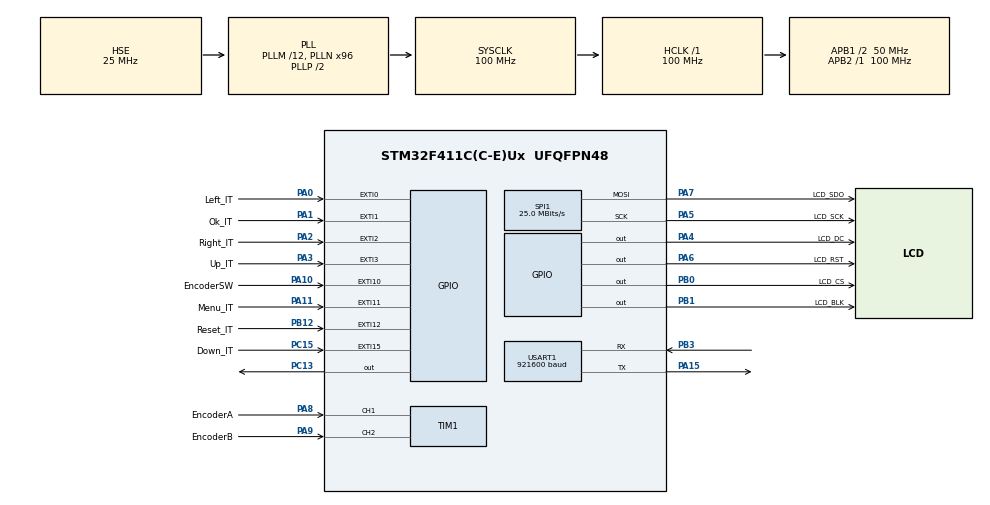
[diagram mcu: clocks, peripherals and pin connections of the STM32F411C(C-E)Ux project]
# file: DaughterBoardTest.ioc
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Dma.MEMTOMEM.1.Direction=DMA_MEMORY_TO_MEMORY
Dma.MEMTOMEM.1.FIFOMode=DMA_FIFOMODE_ENABLE
Dma.MEMTOMEM.1.FIFOThreshold=DMA_FIFO_THRESHOLD_FULL
Dma.MEMTOMEM.1.Instance=DMA2_Stream0
Dma.MEMTOMEM.1.MemBurst=DMA_MBURST_SINGLE
Dma.MEMTOMEM.1.MemDataAlignment=DMA_MDATAALIGN_HALFWORD
Dma.MEMTOMEM.1.MemInc=DMA_MINC_ENABLE
Dma.MEMTOMEM.1.Mode=DMA_NORMAL
Dma.MEMTOMEM.1.PeriphBurst=DMA_PBURST_SINGLE
Dma.MEMTOMEM.1.PeriphDataAlignment=DMA_PDATAALIGN_HALFWORD
Dma.MEMTOMEM.1.PeriphInc=DMA_PINC_ENABLE
Dma.MEMTOMEM.1.Priority=DMA_PRIORITY_LOW
Dma.Request0=SPI1_TX
Dma.Request1=MEMTOMEM
Dma.SPI1_TX.0.Direction=DMA_MEMORY_TO_PERIPH
Dma.SPI1_TX.0.FIFOMode=DMA_FIFOMODE_DISABLE
Dma.SPI1_TX.0.Instance=DMA2_Stream2
Dma.SPI1_TX.0.MemDataAlignment=DMA_MDATAALIGN_BYTE
Dma.SPI1_TX.0.MemInc=DMA_MINC_ENABLE
Dma.SPI1_TX.0.Mode=DMA_NORMAL
Dma.SPI1_TX.0.PeriphDataAlignment=DMA_PDATAALIGN_BYTE
Dma.SPI1_TX.0.PeriphInc=DMA_PINC_DISABLE
Dma.SPI1_TX.0.Priority=DMA_PRIORITY_MEDIUM
Mcu.Family=STM32F4
Mcu.Name=STM32F411C(C-E)Ux
Mcu.Package=UFQFPN48
NVIC.DMA2_Stream0_IRQn=true\:0\:0\:false\:false\:true\:true\:true\:true
NVIC.DMA2_Stream2_IRQn=true\:0\:0\:false\:false\:true\:false\:true\:true
NVIC.EXTI0_IRQn=true\:0\:0\:false\:false\:true\:true\:true\:true
NVIC.EXTI15_10_IRQn=true\:0\:0\:false\:false\:true\:true\:true\:true
NVIC.EXTI1_IRQn=true\:0\:0\:false\:false\:true\:true\:true\:true
NVIC.EXTI2_IRQn=true\:0\:0\:false\:false\:true\:true\:true\:true
NVIC.EXTI3_IRQn=true\:0\:0\:false\:false\:true\:true\:true\:true
NVIC.PriorityGroup=NVIC_PRIORITYGROUP_4
NVIC.TIM2_IRQn=true\:0\:0\:false\:false\:true\:true\:true\:true
PA0-WKUP.GPIO_Label=Left_IT
PA0-WKUP.GPIO_ModeDefaultEXTI=GPIO_MODE_IT_FALLING
PA0-WKUP.GPIO_PuPd=GPIO_PULLUP
PA0-WKUP.Signal=GPXTI0
PA1.GPIO_Label=Ok_IT
PA1.GPIO_ModeDefaultEXTI=GPIO_MODE_IT_FALLING
PA1.GPIO_PuPd=GPIO_PULLUP
PA1.Signal=GPXTI1
PA10.GPIO_Label=EncoderSW
PA10.GPIO_ModeDefaultEXTI=GPIO_MODE_IT_FALLING
PA10.GPIO_PuPd=GPIO_PULLUP
PA10.Signal=GPXTI10
PA11.GPIO_Label=Menu_IT
PA11.GPIO_ModeDefaultEXTI=GPIO_MODE_IT_FALLING
PA11.GPIO_PuPd=GPIO_PULLUP
PA11.Signal=GPXTI11
PA13.Mode=Serial_Wire
PA13.Signal=SYS_JTMS-SWDIO
PA14.Mode=Serial_Wire
PA14.Signal=SYS_JTCK-SWCLK
PA15.Mode=Asynchronous
PA15.Signal=USART1_TX
PA2.GPIO_Label=Right_IT
PA2.GPIO_ModeDefaultEXTI=GPIO_MODE_IT_FALLING
PA2.GPIO_PuPd=GPIO_PULLUP
PA2.Signal=GPXTI2
PA3.GPIO_Label=Up_IT
PA3.GPIO_ModeDefaultEXTI=GPIO_MODE_IT_FALLING
PA3.GPIO_PuPd=GPIO_PULLUP
PA3.Signal=GPXTI3
PA4.GPIO_Label=LCD_DC
PA4.GPIO_PuPd=GPIO_PULLUP
PA4.GPIO_Speed=GPIO_SPEED_FREQ_VERY_HIGH
PA4.PinState=GPIO_PIN_SET
PA4.Signal=GPIO_Output
PA5.GPIO_Label=LCD_SCK
PA5.Mode=TX_Only_Simplex_Unidirect_Master
PA5.Signal=SPI1_SCK
PA6.GPIO_Label=LCD_RST
PA6.GPIO_PuPd=GPIO_PULLUP
PA6.GPIO_Speed=GPIO_SPEED_FREQ_VERY_HIGH
PA6.PinState=GPIO_PIN_SET
PA6.Signal=GPIO_Output
PA7.GPIO_Label=LCD_SDO
PA7.Mode=TX_Only_Simplex_Unidirect_Master
PA7.Signal=SPI1_MOSI
PA8.GPIO_Label=EncoderA
PA8.GPIO_PuPd=GPIO_PULLUP
PA8.Signal=S_TIM1_CH1
PA9.GPIO_Label=EncoderB
PA9.GPIO_PuPd=GPIO_PULLUP
PA9.Signal=S_TIM1_CH2
PB0.GPIO_Label=LCD_CS
PB0.GPIO_ModeDefaultOutputPP=GPIO_MODE_OUTPUT_PP
PB0.GPIO_PuPd=GPIO_PULLUP
PB0.GPIO_Speed=GPIO_SPEED_FREQ_VERY_HIGH
PB0.PinState=GPIO_PIN_SET
PB0.Signal=GPIO_Output
PB1.GPIO_Label=LCD_BLK
PB1.GPIO_PuPd=GPIO_PULLUP
PB1.GPIO_Speed=GPIO_SPEED_FREQ_VERY_HIGH
PB1.PinState=GPIO_PIN_SET
PB1.Signal=GPIO_Output
PB12.GPIO_Label=Reset_IT
PB12.GPIO_ModeDefaultEXTI=GPIO_MODE_IT_FALLING
PB12.GPIO_PuPd=GPIO_PULLUP
PB12.Signal=GPXTI12
PB3.Mode=Asynchronous
PB3.Signal=USART1_RX
PC13-ANTI_TAMP.Signal=GPIO_Output
PC15-OSC32_OUT.GPIO_Label=Down_IT
PC15-OSC32_OUT.GPIO_ModeDefaultEXTI=GPIO_MODE_IT_FALLING
PC15-OSC32_OUT.GPIO_PuPd=GPIO_PULLUP
PC15-OSC32_OUT.Signal=GPXTI15
PH0\ -\ OSC_IN.Mode=HSE-External-Oscillator
PH0\ -\ OSC_IN.Signal=RCC_OSC_IN
PH1\ -\ OSC_OUT.Mode=HSE-External-Oscillator
PH1\ -\ OSC_OUT.Signal=RCC_OSC_OUT
ProjectManager.HeapSize=0x200
ProjectManager.StackSize=0x400
ProjectManager.TargetToolchain=STM32CubeIDE
RCC.48MHZClocksFreq_Value=50000000
RCC.AHBFreq_Value=100000000
RCC.APB1CLKDivider=RCC_HCLK_DIV2
RCC.APB1Freq_Value=50000000
RCC.APB1TimFreq_Value=100000000
RCC.APB2Freq_Value=100000000
RCC.APB2TimFreq_Value=100000000
RCC.CortexFreq_Value=100000000
RCC.HCLKFreq_Value=100000000
RCC.HSE_VALUE=25000000
RCC.HSI_VALUE=16000000
RCC.LSE_VALUE=32768
RCC.PLLM=12
RCC.PLLN=96
RCC.PLLSourceVirtual=RCC_PLLSOURCE_HSE
RCC.SYSCLKFreq_VALUE=100000000
RCC.SYSCLKSource=RCC_SYSCLKSOURCE_PLLCLK
RCC.VCOOutputFreq_Value=200000000
SH.S_TIM1_CH1.0=TIM1_CH1,Encoder_Interface
SH.S_TIM1_CH2.0=TIM1_CH2,Encoder_Interface
SPI1.BaudRatePrescaler=SPI_BAUDRATEPRESCALER_4
SPI1.CLKPolarity=SPI_POLARITY_HIGH
SPI1.CalculateBaudRate=25.0 MBits/s
SPI1.Direction=SPI_DIRECTION_2LINES
SPI1.Mode=SPI_MODE_MASTER
SPI1.VirtualType=VM_MASTER
TIM1.IC1Filter=10
TIM1.IC2Filter=10
TIM2.AutoReloadPreload=TIM_AUTORELOAD_PRELOAD_ENABLE
TIM2.Period=49999
TIM2.Prescaler=1
USART1.BaudRate=921600
USART1.Parity=PARITY_EVEN
USART1.VirtualMode=VM_ASYNC
USART1.WordLength=WORDLENGTH_9B
VP_TIM2_VS_ClockSourceINT.Mode=Internal
board=custom

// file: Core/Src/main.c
#include "main.h"
#include "lcd.h"
#include "UI.h"
#include <stdio.h>
#include <string.h>

#define LCD_TEST
#define LCD_UI_DESIGN

#define TimerMiddleValue 0x7FFF //0xFFFF/2
#define TimerValue TimerMiddleValue>>2 //1FFF
#define EncoderGetVal(x) x = (int32_t)(((TIM1 -> CNT)>>2) - (TimerValue))

SPI_HandleTypeDef hspi1;
DMA_HandleTypeDef hdma_spi1_tx;

TIM_HandleTypeDef htim1;
TIM_HandleTypeDef htim2;

UART_HandleTypeDef huart1;

DMA_HandleTypeDef hdma_memtomem_dma2_stream0;

typedef enum bool
{
	false,
	true
}bool;

void SystemClock_Config(void);
static void MX_GPIO_Init(void);
static void MX_DMA_Init(void);
static void MX_USART1_UART_Init(void);
static void MX_SPI1_Init(void);
static void MX_TIM1_Init(void);
static void MX_TIM2_Init(void);
static void vTaskEncoder(void);

char *Buffer = "SI!";

__IO uint32_t transferErrorDetected;    /* Set to 1 if an error transfer is detected */
__IO uint32_t transferCompleteDetected; /* Set to 1 if transfer is correctly completed */

bool ParsedFlag = true;
MenuStage menuStage = sInitialAnim;
Input input;

int main(void)
{
  HAL_Init();
  SystemClock_Config();
  MX_GPIO_Init();
  MX_DMA_Init();
  MX_USART1_UART_Init();
  MX_SPI1_Init();
  MX_TIM1_Init();
  MX_TIM2_Init();

  LCD_init();

#ifdef LCD_TEST
  LCD_Test();
  UG_FillScreen(0);
  UG_Update();
#endif

  HAL_TIM_Encoder_Start(&htim1, TIM_CHANNEL_ALL);
  HAL_TIM_Base_Start_IT(&htim2);
  while (1)
  {
	  vTaskEncoder();
	  vTaskUI(&menuStage, &input);
	  ParsedFlag = true;
	  while(ParsedFlag);
  }
}

static void vTaskEncoder(void)
{
	static uint16_t EncoderCount = TimerMiddleValue;
	static uint16_t EncoderPastCount = TimerMiddleValue;
	char Buffer[32] = "";

	EncoderGetVal(EncoderCount);
	if(EncoderCount != EncoderPastCount)
	{
		sprintf(Buffer, "Encoder: %d!", (int)EncoderCount);
		HAL_UART_Transmit(&huart1, (uint8_t*)Buffer, strlen(Buffer), 100);
	}
	EncoderPastCount = EncoderCount;
}

void HAL_GPIO_EXTI_Callback(uint16_t GPIO_Pin)
{
	if(GPIO_Pin == Ok_IT_Pin)
	{
		char *Buffer = "OK!";
		HAL_UART_Transmit(&huart1, (uint8_t*)Buffer, 3, 100);
		HAL_GPIO_TogglePin(GPIOC, GPIO_PIN_13);
		input = iOk;
	}
	else if(GPIO_Pin == Up_IT_Pin)
	{
		char *Buffer = "Up!";
		HAL_UART_Transmit(&huart1, (uint8_t*)Buffer, 3, 100);
		HAL_GPIO_TogglePin(GPIOC, GPIO_PIN_13);
		input = iUp;
	}
	else if(GPIO_Pin == Down_IT_Pin)
	{
		char *Buffer = "Down!";
		HAL_UART_Transmit(&huart1, (uint8_t*)Buffer, 5, 100);
		HAL_GPIO_TogglePin(GPIOC, GPIO_PIN_13);
		input = iDown;
	}
	else if(GPIO_Pin == Right_IT_Pin)
	{
		char *Buffer = "Right!";
		HAL_UART_Transmit(&huart1, (uint8_t*)Buffer, 6, 100);
		HAL_GPIO_TogglePin(GPIOC, GPIO_PIN_13);
		input = iRight;
	}
	else if(GPIO_Pin == Left_IT_Pin)
	{
		char *Buffer = "Left!";
		HAL_UART_Transmit(&huart1, (uint8_t*)Buffer, 5, 100);
		HAL_GPIO_TogglePin(GPIOC, GPIO_PIN_13);
		input = iLeft;
	}
	else if(GPIO_Pin == Menu_IT_Pin)
	{
		char *Buffer = "Menu!";
		HAL_UART_Transmit(&huart1, (uint8_t*)Buffer, 5, 100);
		HAL_GPIO_TogglePin(GPIOC, GPIO_PIN_13);
		input = iMenu;
	}
	else if(GPIO_Pin == Reset_IT_Pin)
	{
		char *Buffer = "Reset!";
		HAL_UART_Transmit(&huart1, (uint8_t*)Buffer, 6, 100);
		HAL_GPIO_TogglePin(GPIOC, GPIO_PIN_13);
		input = iReset;
	}
	else if(GPIO_Pin == EncoderSW_Pin)
	{
		char *Buffer = "EncoderSW!";
		HAL_UART_Transmit(&huart1, (uint8_t*)Buffer, 10, 100);
		HAL_GPIO_TogglePin(GPIOC, GPIO_PIN_13);
		input = iEncoder;
	}
}

void HAL_TIM_PeriodElapsedCallback(TIM_HandleTypeDef *htim)
{
	ParsedFlag = false;
}

static void TransferComplete(DMA_HandleTypeDef *DmaHandle)
{
  transferCompleteDetected = 1;
}

static void TransferError(DMA_HandleTypeDef *DmaHandle)
{
  transferErrorDetected = 1;
}

void SystemClock_Config(void)
{
  RCC_OscInitTypeDef RCC_OscInitStruct = {0};
  RCC_ClkInitTypeDef RCC_ClkInitStruct = {0};

  /** Configure the main internal regulator output voltage
  */
  __HAL_RCC_PWR_CLK_ENABLE();
  __HAL_PWR_VOLTAGESCALING_CONFIG(PWR_REGULATOR_VOLTAGE_SCALE1);

  /** Initializes the RCC Oscillators according to the specified parameters
  * in the RCC_OscInitTypeDef structure.
  */
  RCC_OscInitStruct.OscillatorType = RCC_OSCILLATORTYPE_HSE;
  RCC_OscInitStruct.HSEState = RCC_HSE_ON;
  RCC_OscInitStruct.PLL.PLLState = RCC_PLL_ON;
  RCC_OscInitStruct.PLL.PLLSource = RCC_PLLSOURCE_HSE;
  RCC_OscInitStruct.PLL.PLLM = 12;
  RCC_OscInitStruct.PLL.PLLN = 96;
  RCC_OscInitStruct.PLL.PLLP = RCC_PLLP_DIV2;
  RCC_OscInitStruct.PLL.PLLQ = 4;
  if (HAL_RCC_OscConfig(&RCC_OscInitStruct) != HAL_OK)
  {
    Error_Handler();
  }

  /** Initializes the CPU, AHB and APB buses clocks
  */
  RCC_ClkInitStruct.ClockType = RCC_CLOCKTYPE_HCLK|RCC_CLOCKTYPE_SYSCLK
                              |RCC_CLOCKTYPE_PCLK1|RCC_CLOCKTYPE_PCLK2;
  RCC_ClkInitStruct.SYSCLKSource = RCC_SYSCLKSOURCE_PLLCLK;
  RCC_ClkInitStruct.AHBCLKDivider = RCC_SYSCLK_DIV1;
  RCC_ClkInitStruct.APB1CLKDivider = RCC_HCLK_DIV2;
  RCC_ClkInitStruct.APB2CLKDivider = RCC_HCLK_DIV1;

  if (HAL_RCC_ClockConfig(&RCC_ClkInitStruct, FLASH_LATENCY_3) != HAL_OK)
  {
    Error_Handler();
  }
}

static void MX_SPI1_Init(void)
{

  /* SPI1 parameter configuration*/
  hspi1.Instance = SPI1;
  hspi1.Init.Mode = SPI_MODE_MASTER;
  hspi1.Init.Direction = SPI_DIRECTION_2LINES;
  hspi1.Init.DataSize = SPI_DATASIZE_8BIT;
  hspi1.Init.CLKPolarity = SPI_POLARITY_HIGH;
  hspi1.Init.CLKPhase = SPI_PHASE_1EDGE;
  hspi1.Init.NSS = SPI_NSS_SOFT;
  hspi1.Init.BaudRatePrescaler = SPI_BAUDRATEPRESCALER_2;
  hspi1.Init.FirstBit = SPI_FIRSTBIT_MSB;
  hspi1.Init.TIMode = SPI_TIMODE_DISABLE;
  hspi1.Init.CRCCalculation = SPI_CRCCALCULATION_DISABLE;
  hspi1.Init.CRCPolynomial = 10;
  if (HAL_SPI_Init(&hspi1) != HAL_OK)
  {
    Error_Handler();
  }

}

static void MX_TIM1_Init(void)
{

  TIM_Encoder_InitTypeDef sConfig = {0};
  TIM_MasterConfigTypeDef sMasterConfig = {0};

  htim1.Instance = TIM1;
  htim1.Init.Prescaler = 0;
  htim1.Init.CounterMode = TIM_COUNTERMODE_UP;
  htim1.Init.Period = 65535;
  htim1.Init.ClockDivision = TIM_CLOCKDIVISION_DIV1;
  htim1.Init.RepetitionCounter = 0;
  htim1.Init.AutoReloadPreload = TIM_AUTORELOAD_PRELOAD_DISABLE;
  sConfig.EncoderMode = TIM_ENCODERMODE_TI1;
  sConfig.IC1Polarity = TIM_ICPOLARITY_RISING;
  sConfig.IC1Selection = TIM_ICSELECTION_DIRECTTI;
  sConfig.IC1Prescaler = TIM_ICPSC_DIV1;
  sConfig.IC1Filter = 10;
  sConfig.IC2Polarity = TIM_ICPOLARITY_RISING;
  sConfig.IC2Selection = TIM_ICSELECTION_DIRECTTI;
  sConfig.IC2Prescaler = TIM_ICPSC_DIV1;
  sConfig.IC2Filter = 10;
  if (HAL_TIM_Encoder_Init(&htim1, &sConfig) != HAL_OK)
  {
    Error_Handler();
  }
  sMasterConfig.MasterOutputTrigger = TIM_TRGO_RESET;
  sMasterConfig.MasterSlaveMode = TIM_MASTERSLAVEMODE_DISABLE;
  if (HAL_TIMEx_MasterConfigSynchronization(&htim1, &sMasterConfig) != HAL_OK)
  {
    Error_Handler();
  }

}

static void MX_TIM2_Init(void)
{

  TIM_ClockConfigTypeDef sClockSourceConfig = {0};
  TIM_MasterConfigTypeDef sMasterConfig = {0};

  htim2.Instance = TIM2;
  htim2.Init.Prescaler = 1;
  htim2.Init.CounterMode = TIM_COUNTERMODE_UP;
  htim2.Init.Period = 49999;
  htim2.Init.ClockDivision = TIM_CLOCKDIVISION_DIV1;
  htim2.Init.AutoReloadPreload = TIM_AUTORELOAD_PRELOAD_ENABLE;
  if (HAL_TIM_Base_Init(&htim2) != HAL_OK)
  {
    Error_Handler();
  }
  sClockSourceConfig.ClockSource = TIM_CLOCKSOURCE_INTERNAL;
  if (HAL_TIM_ConfigClockSource(&htim2, &sClockSourceConfig) != HAL_OK)
  {
    Error_Handler();
  }
  sMasterConfig.MasterOutputTrigger = TIM_TRGO_RESET;
  sMasterConfig.MasterSlaveMode = TIM_MASTERSLAVEMODE_DISABLE;
  if (HAL_TIMEx_MasterConfigSynchronization(&htim2, &sMasterConfig) != HAL_OK)
  {
    Error_Handler();
  }

}

static void MX_USART1_UART_Init(void)
{

  huart1.Instance = USART1;
  huart1.Init.BaudRate = 921600;
  huart1.Init.WordLength = UART_WORDLENGTH_9B;
  huart1.Init.StopBits = UART_STOPBITS_1;
  huart1.Init.Parity = UART_PARITY_EVEN;
  huart1.Init.Mode = UART_MODE_TX_RX;
  huart1.Init.HwFlowCtl = UART_HWCONTROL_NONE;
  huart1.Init.OverSampling = UART_OVERSAMPLING_16;
  if (HAL_UART_Init(&huart1) != HAL_OK)
  {
    Error_Handler();
  }

}

static void MX_DMA_Init(void)
{

  /* DMA controller clock enable */
  __HAL_RCC_DMA2_CLK_ENABLE();

  /* Configure DMA request hdma_memtomem_dma2_stream0 on DMA2_Stream0 */
  hdma_memtomem_dma2_stream0.Instance = DMA2_Stream0;
  hdma_memtomem_dma2_stream0.Init.Channel = DMA_CHANNEL_0;
  hdma_memtomem_dma2_stream0.Init.Direction = DMA_MEMORY_TO_MEMORY;
  hdma_memtomem_dma2_stream0.Init.PeriphInc = DMA_PINC_ENABLE;
  hdma_memtomem_dma2_stream0.Init.MemInc = DMA_MINC_ENABLE;
  hdma_memtomem_dma2_stream0.Init.PeriphDataAlignment = DMA_PDATAALIGN_HALFWORD;
  hdma_memtomem_dma2_stream0.Init.MemDataAlignment = DMA_MDATAALIGN_HALFWORD;
  hdma_memtomem_dma2_stream0.Init.Mode = DMA_NORMAL;
  hdma_memtomem_dma2_stream0.Init.Priority = DMA_PRIORITY_LOW;
  hdma_memtomem_dma2_stream0.Init.FIFOMode = DMA_FIFOMODE_ENABLE;
  hdma_memtomem_dma2_stream0.Init.FIFOThreshold = DMA_FIFO_THRESHOLD_FULL;
  hdma_memtomem_dma2_stream0.Init.MemBurst = DMA_MBURST_SINGLE;
  hdma_memtomem_dma2_stream0.Init.PeriphBurst = DMA_PBURST_SINGLE;
  if (HAL_DMA_Init(&hdma_memtomem_dma2_stream0) != HAL_OK)
  {
    Error_Handler( );
  }

  /* USER CODE BEGIN DMA_Init */
  HAL_DMA_RegisterCallback(&hdma_memtomem_dma2_stream0, HAL_DMA_XFER_CPLT_CB_ID, TransferComplete);
  HAL_DMA_RegisterCallback(&hdma_memtomem_dma2_stream0, HAL_DMA_XFER_ERROR_CB_ID, TransferError);
  /* USER CODE END DMA_Init */

  /* DMA interrupt init */
  /* DMA2_Stream0_IRQn interrupt configuration */
  HAL_NVIC_SetPriority(DMA2_Stream0_IRQn, 0, 0);
  HAL_NVIC_EnableIRQ(DMA2_Stream0_IRQn);
  /* DMA2_Stream2_IRQn interrupt configuration */
  HAL_NVIC_SetPriority(DMA2_Stream2_IRQn, 0, 0);
  HAL_NVIC_EnableIRQ(DMA2_Stream2_IRQn);

}

static void MX_GPIO_Init(void)
{
  GPIO_InitTypeDef GPIO_InitStruct = {0};

  /* GPIO Ports Clock Enable */
  __HAL_RCC_GPIOC_CLK_ENABLE();
  __HAL_RCC_GPIOH_CLK_ENABLE();
  __HAL_RCC_GPIOA_CLK_ENABLE();
  __HAL_RCC_GPIOB_CLK_ENABLE();

  /*Configure GPIO pin Output Level */
  HAL_GPIO_WritePin(GPIOC, GPIO_PIN_13, GPIO_PIN_RESET);

  /*Configure GPIO pin Output Level */
  HAL_GPIO_WritePin(GPIOA, LCD_DC_Pin|LCD_RST_Pin, GPIO_PIN_SET);

  /*Configure GPIO pin Output Level */
  HAL_GPIO_WritePin(GPIOB, LCD_CS_Pin|LCD_BLK_Pin, GPIO_PIN_SET);

  /*Configure GPIO pin : PC13 */
  GPIO_InitStruct.Pin = GPIO_PIN_13;
  GPIO_InitStruct.Mode = GPIO_MODE_OUTPUT_PP;
  GPIO_InitStruct.Pull = GPIO_NOPULL;
  GPIO_InitStruct.Speed = GPIO_SPEED_FREQ_LOW;
  HAL_GPIO_Init(GPIOC, &GPIO_InitStruct);

  /*Configure GPIO pin : Down_IT_Pin */
  GPIO_InitStruct.Pin = Down_IT_Pin;
  GPIO_InitStruct.Mode = GPIO_MODE_IT_FALLING;
  GPIO_InitStruct.Pull = GPIO_PULLUP;
  HAL_GPIO_Init(Down_IT_GPIO_Port, &GPIO_InitStruct);

  /*Configure GPIO pins : Left_IT_Pin Ok_IT_Pin Right_IT_Pin Up_IT_Pin
                           EncoderSW_Pin Menu_IT_Pin */
  GPIO_InitStruct.Pin = Left_IT_Pin|Ok_IT_Pin|Right_IT_Pin|Up_IT_Pin
                          |EncoderSW_Pin|Menu_IT_Pin;
  GPIO_InitStruct.Mode = GPIO_MODE_IT_FALLING;
  GPIO_InitStruct.Pull = GPIO_PULLUP;
  HAL_GPIO_Init(GPIOA, &GPIO_InitStruct);

  /*Configure GPIO pins : LCD_DC_Pin LCD_RST_Pin */
  GPIO_InitStruct.Pin = LCD_DC_Pin|LCD_RST_Pin;
  GPIO_InitStruct.Mode = GPIO_MODE_OUTPUT_PP;
  GPIO_InitStruct.Pull = GPIO_PULLUP;
  GPIO_InitStruct.Speed = GPIO_SPEED_FREQ_VERY_HIGH;
  HAL_GPIO_Init(GPIOA, &GPIO_InitStruct);

  /*Configure GPIO pins : LCD_CS_Pin LCD_BLK_Pin */
  GPIO_InitStruct.Pin = LCD_CS_Pin|LCD_BLK_Pin;
  GPIO_InitStruct.Mode = GPIO_MODE_OUTPUT_PP;
  GPIO_InitStruct.Pull = GPIO_PULLUP;
  GPIO_InitStruct.Speed = GPIO_SPEED_FREQ_VERY_HIGH;
  HAL_GPIO_Init(GPIOB, &GPIO_InitStruct);

  /*Configure GPIO pin : Reset_IT_Pin */
  GPIO_InitStruct.Pin = Reset_IT_Pin;
  GPIO_InitStruct.Mode = GPIO_MODE_IT_FALLING;
  GPIO_InitStruct.Pull = GPIO_PULLUP;
  HAL_GPIO_Init(Reset_IT_GPIO_Port, &GPIO_InitStruct);

  /* EXTI interrupt init*/
  HAL_NVIC_SetPriority(EXTI0_IRQn, 0, 0);
  HAL_NVIC_EnableIRQ(EXTI0_IRQn);

  HAL_NVIC_SetPriority(EXTI1_IRQn, 0, 0);
  HAL_NVIC_EnableIRQ(EXTI1_IRQn);

  HAL_NVIC_SetPriority(EXTI2_IRQn, 0, 0);
  HAL_NVIC_EnableIRQ(EXTI2_IRQn);

  HAL_NVIC_SetPriority(EXTI3_IRQn, 0, 0);
  HAL_NVIC_EnableIRQ(EXTI3_IRQn);

  HAL_NVIC_SetPriority(EXTI15_10_IRQn, 0, 0);
  HAL_NVIC_EnableIRQ(EXTI15_10_IRQn);

}

void Error_Handler(void)
{
  /* USER CODE BEGIN Error_Handler_Debug */
  /* User can add his own implementation to report the HAL error return state */
  __disable_irq();
  while (1)
  {
	  HAL_GPIO_TogglePin(GPIOC, GPIO_PIN_13);
	  for(uint32_t i = 0; i < 500000; i++);
  }
  /* USER CODE END Error_Handler_Debug */
}
